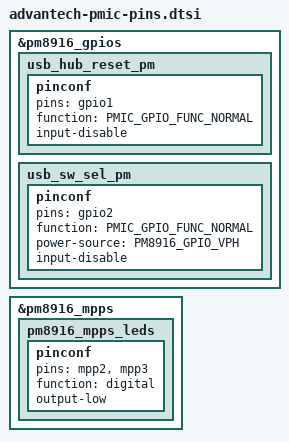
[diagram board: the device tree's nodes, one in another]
#include <dt-bindings/pinctrl/qcom,pmic-gpio.h>
#include <dt-bindings/pinctrl/qcom,pmic-mpp.h>

&pm8916_gpios {

	usb_hub_reset_pm: usb_hub_reset_pm {
		pinconf {
			pins = "gpio1";
			function = PMIC_GPIO_FUNC_NORMAL;
			input-disable;
		};
	};

	usb_sw_sel_pm: usb_sw_sel_pm {
		pinconf {
			pins = "gpio2";
			function = PMIC_GPIO_FUNC_NORMAL;
			power-source = <PM8916_GPIO_VPH>;
			input-disable;
		};
	};
};

&pm8916_mpps {

	pm8916_mpps_leds: pm8916_mpps_leds {
		pinconf {
			pins = "mpp2", "mpp3";
			function = "digital";
			output-low;
		};
	};
};
